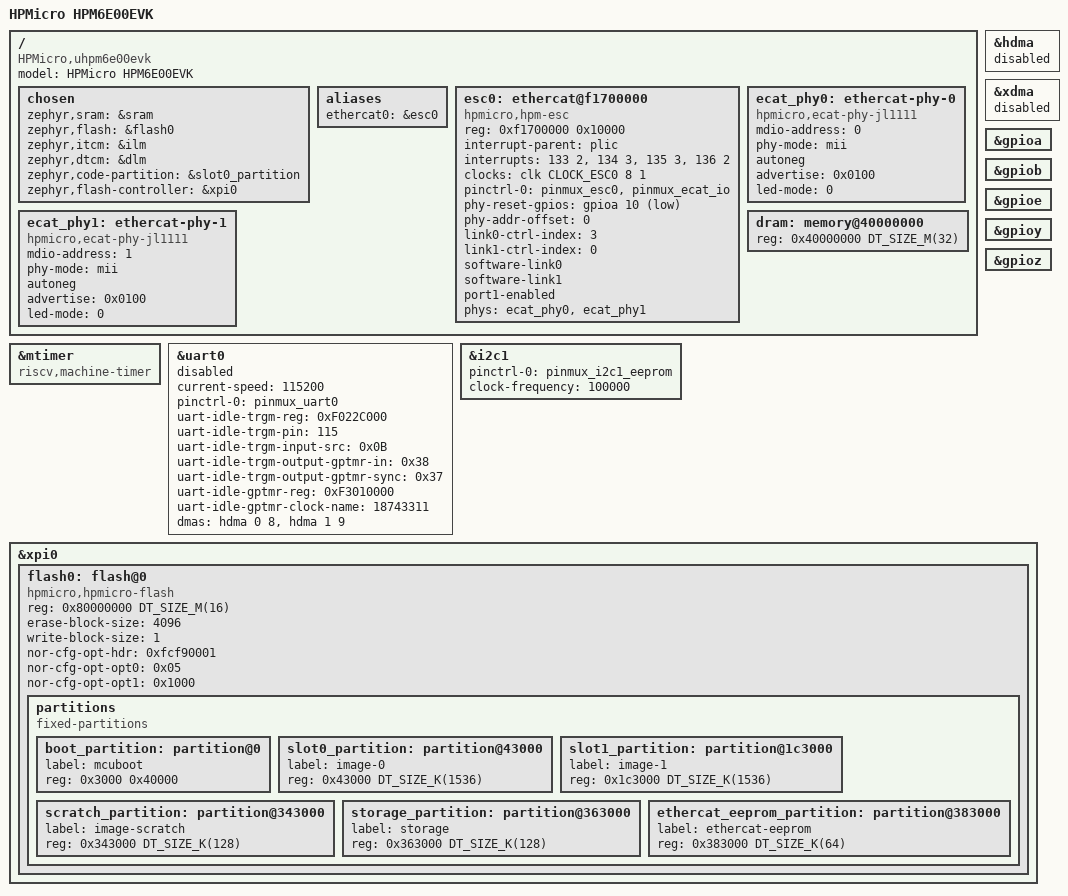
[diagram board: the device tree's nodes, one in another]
/*
 * Copyright 2025 HPMicro
 * SPDX-License-Identifier: Apache-2.0
 */

/dts-v1/;

#include <hpmicro/hpm6e80.dtsi>
#include "uhpm6e00evk-pinctrl.dtsi"

/ {
	model = "HPMicro HPM6E00EVK";
	compatible = "HPMicro,uhpm6e00evk";

	chosen {
		zephyr,sram = &sram;
		zephyr,flash = &flash0;
		zephyr,itcm = &ilm;
		zephyr,dtcm = &dlm;
		zephyr,code-partition = &slot0_partition;
		zephyr,flash-controller = &xpi0;
	};


	aliases {
		ethercat0 = &esc0;
	};

	/**
	 * EtherCAT 从站控制器（片内 ESC）
	 * 依据 HPM6E00EVK RevA 原理图 ETHERCAT_A.kicad_sch：
	 *   - PHY U11 = JL1111-N032I（MII），PORTA Address is 00，PORTA is ECAT IN
	 *   - U12 = CAT24C128 EEPROM（ESC 的 I2C EEPROM）
	 * 中断号取自 hpm_soc_irq.h：ESC=133 / SYNC0=134 / SYNC1=135 / RESET=136
	 */
	esc0: ethercat@f1700000 {
		compatible = "hpmicro,hpm-esc";
		reg = <0xf1700000 0x10000>;
		interrupt-parent = <&plic>;
		interrupts = <133 2>, <134 3>, <135 3>, <136 2>;
		interrupt-names = "pdi", "sync0", "sync1", "reset";
		/* clk 是 #clock-cells=<3>：name/src/div。
		 * ESC0 在 SDK 里只做 clock_add_to_group，不切源不分频，
		 * 这里给 CLK_SRC_GROUP_AXIN(8) 且 div=1，与复位默认一致。 */
		clocks = <&clk CLOCK_ESC0 8 1>;
		/* Zephyr 只内建 default/sleep 两个状态名，自定义状态名要驱动自己
		 * 定义 PINCTRL_STATE_* 并 apply，esc_hpmicro.c 只 apply default。
		 * 所以 ESC 本体和数字 IO 都挂在 pinctrl-0 里，一次配完。 */
		pinctrl-0 = <&pinmux_esc0 &pinmux_ecat_io>;
		pinctrl-names = "default";
		/* PORTA_RESET：原理图 R81 10K 上拉 + C63 0.1uF；MCU 侧引脚为 PA10 */
		phy-reset-gpios = <&gpioa 10 GPIO_ACTIVE_LOW>;
		phy-addr-offset = <0>;
		/* PORTA Address is 00；PORTA_LINK = PA15 → ESC0_CTR_3 */
		link0-ctrl-index = <3>;
		/* PORTB_LINK = PA11 → ESC0_CTR_0 */
		link1-ctrl-index = <0>;
		software-link0;
		software-link1;
		port1-enabled;
		/* 两颗 PHY 都是 JL1111（MII）；驱动由各自的 compatible 选中 */
		phys = <&ecat_phy0 &ecat_phy1>;
		status = "okay";
	};

	/* EtherCAT PHY：PORTA @MDIO0，PORTB @MDIO1（依据 hpm_sdk hpm6e00evk board.h） */
	ecat_phy0: ethercat-phy-0 {
		compatible = "hpmicro,ecat-phy-jl1111";
		mdio-address = <0>;
		phy-mode = "mii";
		autoneg;
		advertise = <0x0100>;      /* 只通告 100BASE-TX 全双工 */
		led-mode = <0>;
	};

	ecat_phy1: ethercat-phy-1 {
		compatible = "hpmicro,ecat-phy-jl1111";
		mdio-address = <1>;
		phy-mode = "mii";
		autoneg;
		advertise = <0x0100>;
		led-mode = <0>;
	};

	dram: memory@40000000 {
		device_type = "memory";
		reg = <0x40000000 DT_SIZE_M(32)>;
	};
};

/* Zephyr 机器定时器需要 riscv,machine-timer 这一级的 compatible */
&mtimer {
	compatible = "riscv,machine-timer", "andestech,machine-timer";
	reg-names = "mtime", "mtimecmp";
};

&uart0 {
	status = "disabled";
	current-speed = <115200>;
	pinctrl-0 = <&pinmux_uart0>;
	pinctrl-names = "default";
	uart-idle-trgm-reg = <0xF022C000>;
	uart-idle-trgm-pin = <115>;
	uart-idle-trgm-input-src = <0x0B>;
	uart-idle-trgm-output-gptmr-in = <0x38>;
	uart-idle-trgm-output-gptmr-sync = <0x37>;
	uart-idle-gptmr-reg = <0xF3010000>;
	uart-idle-gptmr-clock-name = <18743311>;
	dmas = <&hdma 0 8>, <&hdma 1 9>;
	dma-names = "rx", "tx";
};

&hdma {
	status = "disabled";
};

&xdma {
	status = "disabled";
};

&gpioa {
	status = "okay";
};

/* ESC EEPROM 预烧通道（CAT24C128 挂在 I2C1，地址 0x50） */
&i2c1 {
	status = "okay";
	pinctrl-0 = <&pinmux_i2c1_eeprom>;
	pinctrl-names = "default";
	clock-frequency = <100000>;
};

&gpiob {
	status = "okay";
};

&gpioe {
	status = "okay";
};

&gpioy {
	status = "okay";
};

&gpioz {
	status = "okay";
};

&xpi0 {
	status = "okay";

	flash0: flash@0 {
		compatible = "hpmicro,hpmicro-flash", "soc-nv-flash";
		reg = <0x80000000 DT_SIZE_M(16)>;
		status = "okay";
		erase-block-size = <4096>;
		write-block-size = <1>;
		nor-cfg-opt-hdr = <0xfcf90001>;
		nor-cfg-opt-opt0 = <0x05>;
		nor-cfg-opt-opt1 = <0x1000>;

		partitions {
			compatible = "fixed-partitions";
			#address-cells = <1>;
			#size-cells = <1>;

			boot_partition: partition@0 {
				label = "mcuboot";
				reg = <0x3000 0x40000>;
			};

			slot0_partition: partition@43000 {
				label = "image-0";
				reg = <0x43000 DT_SIZE_K(1536)>;
			};

			slot1_partition: partition@1c3000 {
				label = "image-1";
				reg = <0x1c3000 DT_SIZE_K(1536)>;
			};

			scratch_partition: partition@343000 {
				label = "image-scratch";
				reg = <0x343000 DT_SIZE_K(128)>;
			};

			storage_partition: partition@363000 {
				label = "storage";
				reg = <0x363000 DT_SIZE_K(128)>;
			};

			/* ESC SII 固件模拟 EEPROM：FLASH_EEPROM_SIZE = 0x10000 */
			ethercat_eeprom_partition: partition@383000 {
				label = "ethercat-eeprom";
				reg = <0x383000 DT_SIZE_K(64)>;
			};
		};
	};
};
